AUTOSAR XML (schema 4-3-0)
package /ComponentTypes
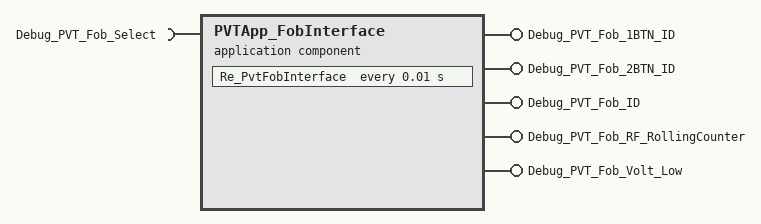
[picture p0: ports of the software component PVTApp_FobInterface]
  application sw component type PVTApp_FobInterface
    5 x provide port:
      Debug_PVT_Fob_1BTN_ID: nonqueued-sender-com-spec{data-element=Debug_PVT_Fob_1BTN_ID, init-value=0}, provided-interface=Debug_PVT_Fob_1BTN_ID
      Debug_PVT_Fob_2BTN_ID: nonqueued-sender-com-spec{data-element=Debug_PVT_Fob_2BTN_ID, init-value=0}, provided-interface=Debug_PVT_Fob_2BTN_ID
      Debug_PVT_Fob_ID: nonqueued-sender-com-spec{data-element=Debug_PVT_Fob_ID, init-value=0}, provided-interface=Debug_PVT_Fob_ID
      Debug_PVT_Fob_RF_RollingCounter: nonqueued-sender-com-spec{data-element=Debug_PVT_Fob_RF_RollingCounter, init-value=0}, provided-interface=Debug_PVT_Fob_RF_RollingCounter
      Debug_PVT_Fob_Volt_Low: nonqueued-sender-com-spec{data-element=Debug_PVT_Fob_Volt_Low, init-value=0}, provided-interface=Debug_PVT_Fob_Volt_Low
    require port Debug_PVT_Fob_Select: nonqueued-receiver-com-spec{data-element=Debug_PVT_Fob_Select, filter=data-filter-type=ALWAYS, init-value=0}, required-interface=Debug_PVT_Fob_Select
    behavior PVTApp_FobInterface_InternalBehavior
      timing event TMT_Re_PvtFobInterface: start-on-event=Re_PvtFobInterface, period=0.01
      runnable Re_PvtFobInterface
        data-receive-point-by-arguments:
          access REC_Debug_PVT_Fob_Select_Debug_PVT_Fob_Select: accessed-variable=Debug_PVT_Fob_Select.Debug_PVT_Fob_Select
        data-send-points:
          5 x access:
            SEND_Debug_PVT_Fob_1BTN_ID_Debug_PVT_Fob_1BTN_ID: accessed-variable=Debug_PVT_Fob_1BTN_ID.Debug_PVT_Fob_1BTN_ID
            SEND_Debug_PVT_Fob_2BTN_ID_Debug_PVT_Fob_2BTN_ID: accessed-variable=Debug_PVT_Fob_2BTN_ID.Debug_PVT_Fob_2BTN_ID
            SEND_Debug_PVT_Fob_ID_Debug_PVT_Fob_ID: accessed-variable=Debug_PVT_Fob_ID.Debug_PVT_Fob_ID
            SEND_Debug_PVT_Fob_RF_RollingCounter_Debug_PVT_Fob_RF_RollingCounter: accessed-variable=Debug_PVT_Fob_RF_RollingCounter.Debug_PVT_Fob_RF_RollingCounter
            SEND_Debug_PVT_Fob_Volt_Low_Debug_PVT_Fob_Volt_Low: accessed-variable=Debug_PVT_Fob_Volt_Low.Debug_PVT_Fob_Volt_Low
  swc implementation PVTApp_FobInterface_Implementation: behavior=PVTApp_FobInterface_InternalBehavior
    code-descriptors:
      code Default: artifact-descriptors=autosar-engineering-object=category=SWSRC
